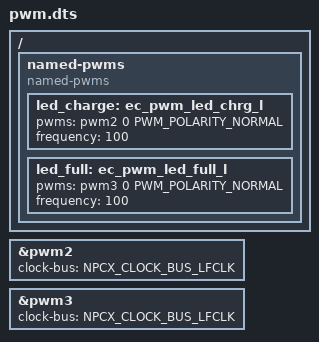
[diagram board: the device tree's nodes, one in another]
/* Copyright 2021 The Chromium OS Authors. All rights reserved.
 * Use of this source code is governed by a BSD-style license that can be
 * found in the LICENSE file.
 */

/ {
	named-pwms {
		compatible = "named-pwms";

		led_charge: ec_pwm_led_chrg_l {
			pwms = <&pwm2 0 PWM_POLARITY_NORMAL>;
			frequency = <100>;
		};
		led_full: ec_pwm_led_full_l {
			pwms = <&pwm3 0 PWM_POLARITY_NORMAL>;
			frequency = <100>;
		};
	};
};

/* Fan control */

/* Amber charging LED */
&pwm2 {
	status = "okay";
	clock-bus = "NPCX_CLOCK_BUS_LFCLK";
};

/* Green full LED */
&pwm3 {
	status = "okay";
	clock-bus = "NPCX_CLOCK_BUS_LFCLK";
};
